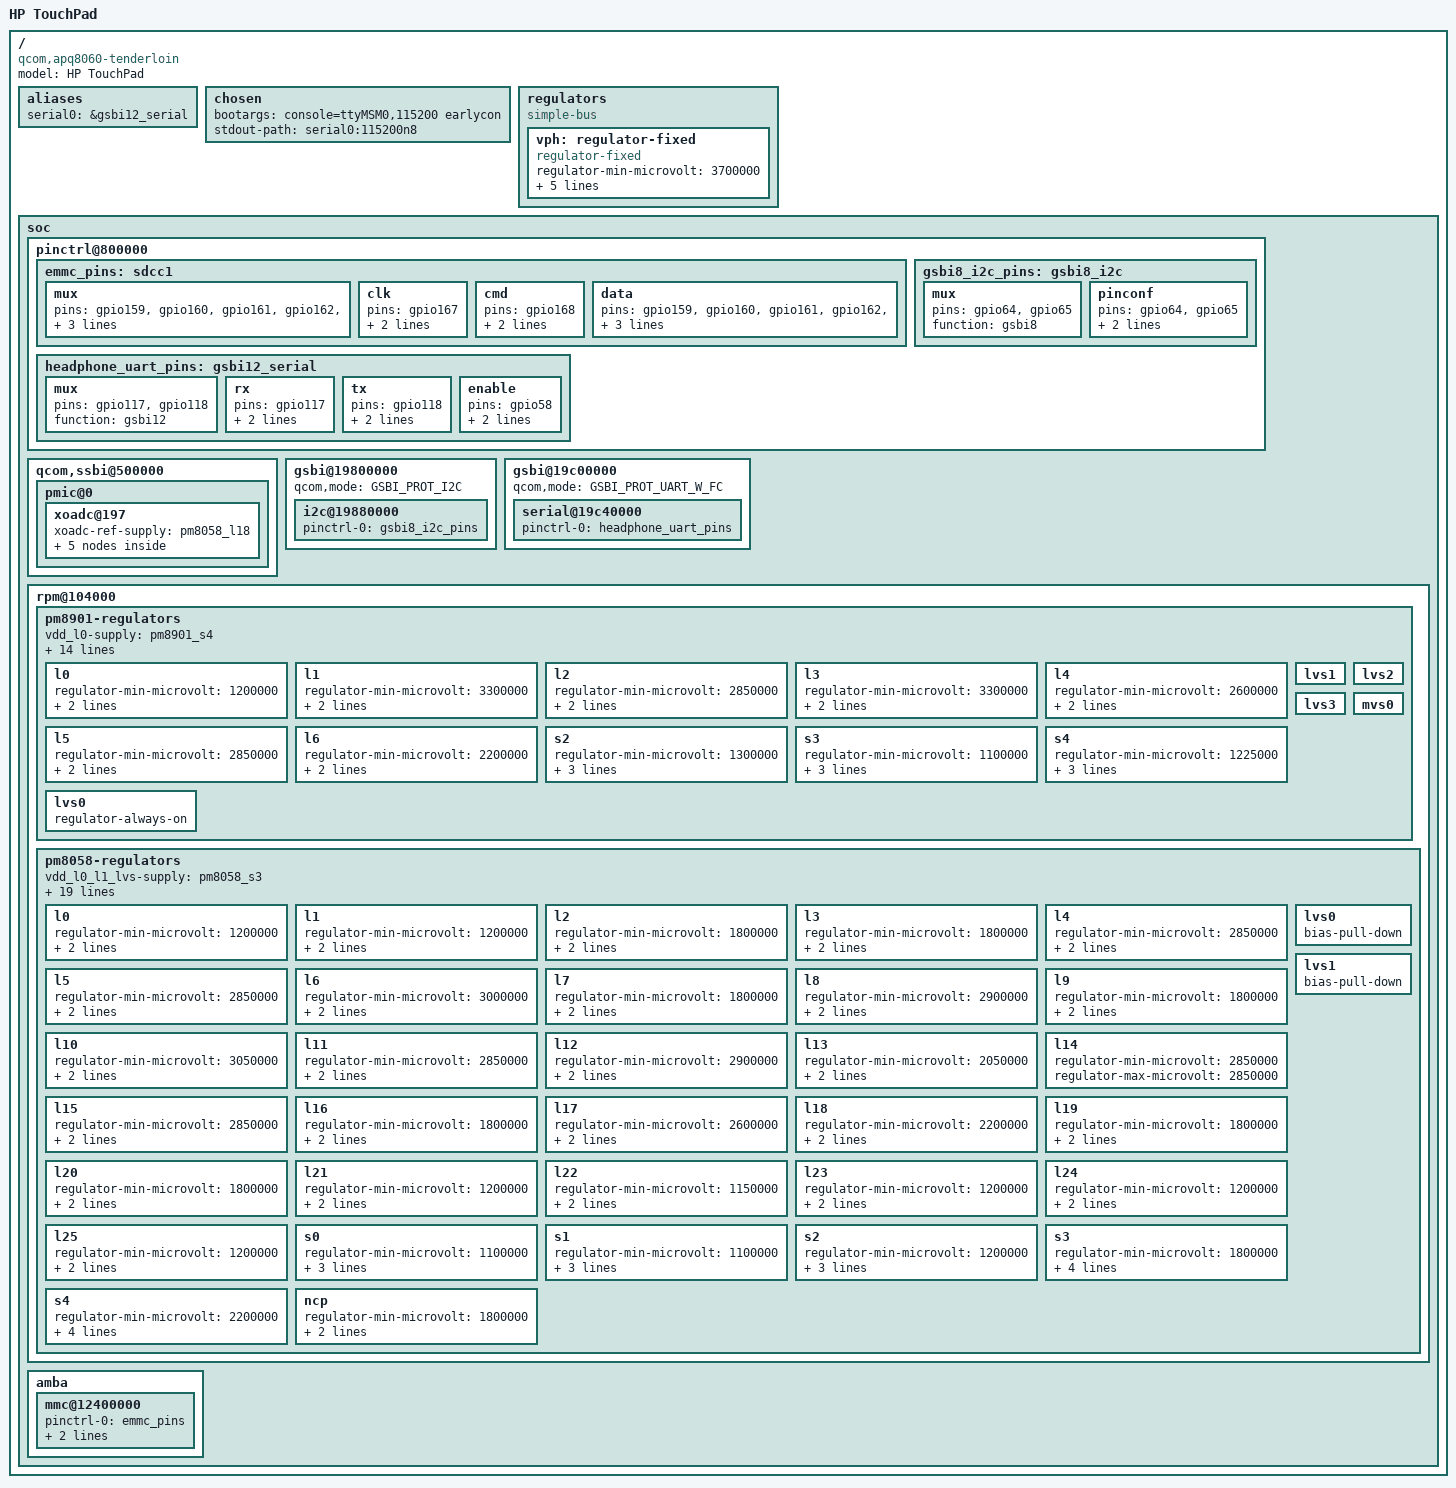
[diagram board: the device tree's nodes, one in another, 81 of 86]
// SPDX-License-Identifier: (GPL-2.0 OR BSD-2-Clause)
#include <dt-bindings/input/input.h>
#include <dt-bindings/gpio/gpio.h>
#include <dt-bindings/pinctrl/qcom,pmic-gpio.h>
#include <dt-bindings/pinctrl/qcom,pmic-mpp.h>
#include "qcom-msm8660.dtsi"

/ {
	model = "HP TouchPad";
	compatible = "qcom,apq8060-tenderloin", "qcom,msm8660";

	aliases {
		serial0 = &gsbi12_serial;
	};

	chosen {
		/* Bootloader passes console=tty1, which overrides stdout-path */
		bootargs = "console=ttyMSM0,115200 earlycon";
		stdout-path = "serial0:115200n8";
	};

	regulators {
		compatible = "simple-bus";

		/* Main power of the board: 3.7V */
		vph: regulator-fixed {
			compatible = "regulator-fixed";
			regulator-min-microvolt = <3700000>;
			regulator-max-microvolt = <3700000>;
			regulator-name = "VPH";
			regulator-type = "voltage";
			regulator-always-on;
			regulator-boot-on;
		};
	};

	soc {
		pinctrl@800000 {
			/* eMMC pins, all 8 data lines connected */
			emmc_pins: sdcc1 {
				mux {
					pins = "gpio159", "gpio160", "gpio161",
					     "gpio162", "gpio163", "gpio164",
					     "gpio165", "gpio166", "gpio167",
					     "gpio168";
					function = "sdc1";
				};
				clk {
					pins = "gpio167"; /* SDC1 CLK */
					drive-strength = <16>;
					bias-disable;
				};
				cmd {
					pins = "gpio168"; /* SDC1 CMD */
					drive-strength = <10>;
					bias-pull-up;
				};
				data {
					/* SDC1 D0 to D7 */
					pins = "gpio159", "gpio160", "gpio161", "gpio162",
					     "gpio163", "gpio164", "gpio165", "gpio166";
					drive-strength = <10>;
					bias-pull-up;
				};
			};

			gsbi8_i2c_pins: gsbi8_i2c {
				mux {
					pins = "gpio64", "gpio65";
					function = "gsbi8";
				};
				pinconf {
					pins = "gpio64", "gpio65";
					drive-strength = <16>;
					/* These have external pull-up 2.2kOhm to 1.8V */
					bias-disable;
				};
			};

			/* Headphone UART pins */
			headphone_uart_pins: gsbi12_serial {
				mux {
					pins = "gpio117", "gpio118";
					function = "gsbi12";
				};
				rx {
					pins = "gpio117";
					drive-strength = <2>;
					bias-pull-up;
				};
				tx {
					pins = "gpio118";
					drive-strength = <8>;
					bias-disable;
				};
				/* Connect headphone jack to UART rather than audio */
				enable {
					pins = "gpio58";
					function = "gpio";
					output-high;
				};
			};
		};

		qcom,ssbi@500000 {
			pmic@0 {
				xoadc@197 {
					/* Reference voltage 2.2 V */
					xoadc-ref-supply = <&pm8058_l18>;

					/* Board-specific channels */
					mpp5@5 {
						/* Connected to AOUT of ALS sensor */
						reg = <0x00 0x05>;
					};
					mpp6@6 {
						/* Connected to test point TP43 */
						reg = <0x00 0x06>;
					};
					mpp7@7 {
						/* Connected to battery thermistor */
						reg = <0x00 0x07>;
					};
					mpp8@8 {
						/* Connected to battery ID detector */
						reg = <0x00 0x08>;
					};
					mpp9@9 {
						/* Connected to XO thermistor */
						reg = <0x00 0x09>;
					};
				};
			};
		};

		gsbi@19800000 {
			status = "okay";
			qcom,mode = <GSBI_PROT_I2C>;

			i2c@19880000 {
				status = "okay";
				pinctrl-names = "default";
				pinctrl-0 = <&gsbi8_i2c_pins>;
			};
		};

		gsbi@19c00000 {
			status = "okay";
			qcom,mode = <GSBI_PROT_UART_W_FC>;

			serial@19c40000 {
				status = "okay";
				pinctrl-names = "default";
				pinctrl-0 = <&headphone_uart_pins>;
			};
		};

		rpm@104000 {
			/*
			 * Set up of the PMIC RPM regulators for this board
			 * PM8901 supplies "preliminary regulators" whatever
			 * that means
			 */
			pm8901-regulators {
				vdd_l0-supply = <&pm8901_s4>;
				vdd_l1-supply = <&vph>;
				vdd_l2-supply = <&vph>;
				vdd_l3-supply = <&vph>;
				vdd_l4-supply = <&vph>;
				vdd_l5-supply = <&vph>;
				vdd_l6-supply = <&vph>;
				/* vdd_s0-supply, vdd_s1-supply: SAW regulators */
				vdd_s2-supply = <&vph>;
				vdd_s3-supply = <&vph>;
				vdd_s4-supply = <&vph>;
				lvs0_in-supply = <&pm8058_s3>;
				lvs1_in-supply = <&pm8901_s4>;
				lvs2_in-supply = <&pm8058_l0>;
				lvs3_in-supply = <&pm8058_s2>;
				mvs_in-supply = <&pm8058_s3>;

				l0 {
					regulator-min-microvolt = <1200000>;
					regulator-max-microvolt = <1200000>;
					bias-pull-down;
				};
				l1 {
					regulator-min-microvolt = <3300000>;
					regulator-max-microvolt = <3300000>;
					bias-pull-down;
				};
				l2 {
					regulator-min-microvolt = <2850000>;
					regulator-max-microvolt = <3300000>;
					bias-pull-down;
				};
				l3 {
					regulator-min-microvolt = <3300000>;
					regulator-max-microvolt = <3300000>;
					bias-pull-down;
				};
				l4 {
					regulator-min-microvolt = <2600000>;
					regulator-max-microvolt = <2600000>;
					bias-pull-down;
				};
				l5 {
					regulator-min-microvolt = <2850000>;
					regulator-max-microvolt = <2850000>;
					bias-pull-down;
				};
				l6 {
					regulator-min-microvolt = <2200000>;
					regulator-max-microvolt = <2200000>;
					bias-pull-down;
				};

				/* s0 and s1 are SAW regulators controlled over SPM */
				s2 {
					regulator-min-microvolt = <1300000>;
					regulator-max-microvolt = <1300000>;
					qcom,switch-mode-frequency = <1600000>;
					bias-pull-down;
				};
				s3 {
					regulator-min-microvolt = <1100000>;
					regulator-max-microvolt = <1100000>;
					qcom,switch-mode-frequency = <1600000>;
					bias-pull-down;
				};
				s4 {
					regulator-min-microvolt = <1225000>;
					regulator-max-microvolt = <1225000>;
					qcom,switch-mode-frequency = <1600000>;
					bias-pull-down;
				};

				/* LVS0 thru 3 and mvs0 are just switches */
				lvs0 {
					regulator-always-on;
				};
				lvs1 { };
				lvs2 { };
				lvs3 { };
				mvs0 {};

			};

			pm8058-regulators {
				vdd_l0_l1_lvs-supply = <&pm8058_s3>;
				vdd_l2_l11_l12-supply = <&vph>;
				vdd_l3_l4_l5-supply = <&vph>;
				vdd_l6_l7-supply = <&vph>;
				vdd_l8-supply = <&vph>;
				vdd_l9-supply = <&vph>;
				vdd_l10-supply = <&vph>;
				vdd_l13_l16-supply = <&pm8058_s4>;
				vdd_l14_l15-supply = <&vph>;
				vdd_l17_l18-supply = <&vph>;
				vdd_l19_l20-supply = <&vph>;
				vdd_l21-supply = <&pm8058_s3>;
				vdd_l22-supply = <&pm8058_s3>;
				vdd_l23_l24_l25-supply = <&pm8058_s3>;
				vdd_s0-supply = <&vph>;
				vdd_s1-supply = <&vph>;
				vdd_s2-supply = <&vph>;
				vdd_s3-supply = <&vph>;
				vdd_s4-supply = <&vph>;
				vdd_ncp-supply = <&vph>;

				l0 {
					regulator-min-microvolt = <1200000>;
					regulator-max-microvolt = <1200000>;
					bias-pull-down;
				};
				l1 {
					regulator-min-microvolt = <1200000>;
					regulator-max-microvolt = <1200000>;
					bias-pull-down;
				};
				l2 {
					regulator-min-microvolt = <1800000>;
					regulator-max-microvolt = <2600000>;
					bias-pull-down;
				};
				l3 {
					regulator-min-microvolt = <1800000>;
					regulator-max-microvolt = <1800000>;
					bias-pull-down;
				};
				l4 {
					regulator-min-microvolt = <2850000>;
					regulator-max-microvolt = <2850000>;
					bias-pull-down;
				};
				l5 {
					regulator-min-microvolt = <2850000>;
					regulator-max-microvolt = <2850000>;
					bias-pull-down;
				};
				l6 {
					regulator-min-microvolt = <3000000>;
					regulator-max-microvolt = <3600000>;
					bias-pull-down;
				};
				l7 {
					regulator-min-microvolt = <1800000>;
					regulator-max-microvolt = <1800000>;
					bias-pull-down;
				};
				l8 {
					regulator-min-microvolt = <2900000>;
					regulator-max-microvolt = <3050000>;
					bias-pull-down;
				};
				l9 {
					regulator-min-microvolt = <1800000>;
					regulator-max-microvolt = <1800000>;
					bias-pull-down;
				};
				l10 {
					regulator-min-microvolt = <3050000>;
					regulator-max-microvolt = <3050000>;
					bias-pull-down;
				};
				l11 {
					regulator-min-microvolt = <2850000>;
					regulator-max-microvolt = <2850000>;
					bias-pull-down;
				};
				l12 {
					regulator-min-microvolt = <2900000>;
					regulator-max-microvolt = <2900000>;
					bias-pull-down;
				};
				l13 {
					regulator-min-microvolt = <2050000>;
					regulator-max-microvolt = <2050000>;
					bias-pull-down;
				};
				l14 {
					regulator-min-microvolt = <2850000>;
					regulator-max-microvolt = <2850000>;
				};
				l15 {
					regulator-min-microvolt = <2850000>;
					regulator-max-microvolt = <2850000>;
					bias-pull-down;
				};
				l16 {
					regulator-min-microvolt = <1800000>;
					regulator-max-microvolt = <1800000>;
					bias-pull-down;
					/*
					 * RPM driver can't handle always-on regulators that are
					 * supplied by regulators initialized after them.
					 */
					// regulator-always-on;
				};
				l17 {
					regulator-min-microvolt = <2600000>;
					regulator-max-microvolt = <2600000>;
					bias-pull-down;
				};
				l18 {
					regulator-min-microvolt = <2200000>;
					regulator-max-microvolt = <2200000>;
					bias-pull-down;
				};
				l19 {
					regulator-min-microvolt = <1800000>;
					regulator-max-microvolt = <1800000>;
					bias-pull-down;
				};
				l20 {
					regulator-min-microvolt = <1800000>;
					regulator-max-microvolt = <1800000>;
					bias-pull-down;
				};
				l21 {
					regulator-min-microvolt = <1200000>;
					regulator-max-microvolt = <1200000>;
					bias-pull-down;
					/*
					 * RPM driver can't handle always-on regulators that are
					 * supplied by regulators initialized after them.
					 */
					// regulator-always-on;
				};
				l22 {
					regulator-min-microvolt = <1150000>;
					regulator-max-microvolt = <1150000>;
					bias-pull-down;
				};
				l23 {
					// Unused
					regulator-min-microvolt = <1200000>;
					regulator-max-microvolt = <1200000>;
					bias-pull-down;
				};
				l24 {
					// Unused
					regulator-min-microvolt = <1200000>;
					regulator-max-microvolt = <1200000>;
					bias-pull-down;
				};
				l25 {
					regulator-min-microvolt = <1200000>;
					regulator-max-microvolt = <1200000>;
					bias-pull-down;
				};

				s0 {
					// regulator-min-microvolt = <800000>;
					// regulator-max-microvolt = <1325000>;
					regulator-min-microvolt = <1100000>;
					regulator-max-microvolt = <1100000>;
					qcom,switch-mode-frequency = <1600000>;
					bias-pull-down;
				};
				s1 {
					// regulator-min-microvolt = <800000>;
					// regulator-max-microvolt = <1325000>;
					regulator-min-microvolt = <1100000>;
					regulator-max-microvolt = <1100000>;
					qcom,switch-mode-frequency = <1600000>;
					bias-pull-down;
				};
				s2 {
					// 1.3 V according to schematic
					regulator-min-microvolt = <1200000>;
					regulator-max-microvolt = <1400000>;
					qcom,switch-mode-frequency = <1600000>;
					bias-pull-down;
				};
				s3 {
					regulator-min-microvolt = <1800000>;
					regulator-max-microvolt = <1800000>;
					qcom,switch-mode-frequency = <1600000>;
					bias-pull-down;
					regulator-always-on;
				};
				s4 {
					regulator-min-microvolt = <2200000>;
					regulator-max-microvolt = <2200000>;
					qcom,switch-mode-frequency = <1600000>;
					bias-pull-down;
					regulator-always-on;
				};

				/* LVS0 and LVS1 are just switches */
				lvs0 {
					bias-pull-down;
				};
				lvs1 {
					bias-pull-down;
				};

				ncp {
					regulator-min-microvolt = <1800000>;
					regulator-max-microvolt = <1800000>;
					qcom,switch-mode-frequency = <1600000>;
				};
			};
		};

		amba {
			/* Internal 16/32 GiB eMMC */
			mmc@12400000 {
				status = "okay";
				pinctrl-names = "default";
				pinctrl-0 = <&emmc_pins>;
				vmmc-supply = <&pm8901_l5>;
				vqmmc-supply = <&pm8901_lvs0>;
			};
		};
	};
};
